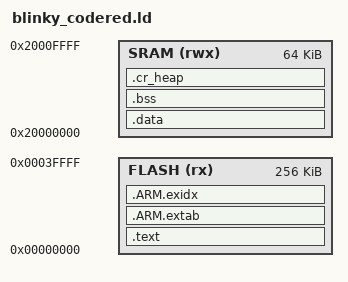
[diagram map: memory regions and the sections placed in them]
/******************************************************************************
 *
 * blinky_codered.ld - Code Red linker configuration file for blinky.
 *
 * Copyright (c) 2009 Luminary Micro, Inc.  All rights reserved.
 * Software License Agreement
 * 
 * Luminary Micro, Inc. (LMI) is supplying this software for use solely and
 * exclusively on LMI's microcontroller products.
 * 
 * The software is owned by LMI and/or its suppliers, and is protected under
 * applicable copyright laws.  All rights are reserved.  You may not combine
 * this software with "viral" open-source software in order to form a larger
 * program.  Any use in violation of the foregoing restrictions may subject
 * the user to criminal sanctions under applicable laws, as well as to civil
 * liability for the breach of the terms and conditions of this license.
 * 
 * THIS SOFTWARE IS PROVIDED "AS IS".  NO WARRANTIES, WHETHER EXPRESS, IMPLIED
 * OR STATUTORY, INCLUDING, BUT NOT LIMITED TO, IMPLIED WARRANTIES OF
 * MERCHANTABILITY AND FITNESS FOR A PARTICULAR PURPOSE APPLY TO THIS SOFTWARE.
 * LMI SHALL NOT, IN ANY CIRCUMSTANCES, BE LIABLE FOR SPECIAL, INCIDENTAL, OR
 * CONSEQUENTIAL DAMAGES, FOR ANY REASON WHATSOEVER.
 * 
 * This is part of revision 32 of the Stellaris CMSIS Package.
 *
 *****************************************************************************/

MEMORY
{
    FLASH (rx) : ORIGIN = 0x00000000, LENGTH = 0x00040000
    SRAM (rwx) : ORIGIN = 0x20000000, LENGTH = 0x00010000
}

SECTIONS
{
    _vRamTop = 0x20000000 + 0x00010000;
    .text :
    {
        KEEP(*(.isr_vector))
        *(.text*)
        *(.rodata*)
    } > FLASH

    /*
     * for exception handling/unwind - some Newlib functions (in common with
     * C++ and STDC++) use this.
     */

    .ARM.extab :
    {
        *(.ARM.extab* .gnu.linkonce.armextab.*)
    } > FLASH

    .ARM.exidx :
    {
        __exidx_start = .;
        *(.ARM.exidx* .gnu.linkonce.armexidx.*)
        __exidx_end = .;
    } > FLASH

    _etext = .;

    .data : AT (__exidx_end)
    {
        _data = .;
        *(vtable)
        *(.data*)
        _edata = .;
    } > SRAM

    /* zero initialized data */

    .bss :
    {
        _bss = .;
        *(.bss*)
        *(COMMON)
        _ebss = .;
    } > SRAM

    /* Where we put the heap with cr_clib */

    .cr_heap :
    {
        end = .;
        _pvHeapStart = .;
    } > SRAM

    /*
     * Note: (ref: M0000066)
     * Moving the stack down by 16 is to work around a GDB bug.
     * This space can be reclaimed for Production Builds.
     */

    _vStackTop = _vRamTop - 16;
}
